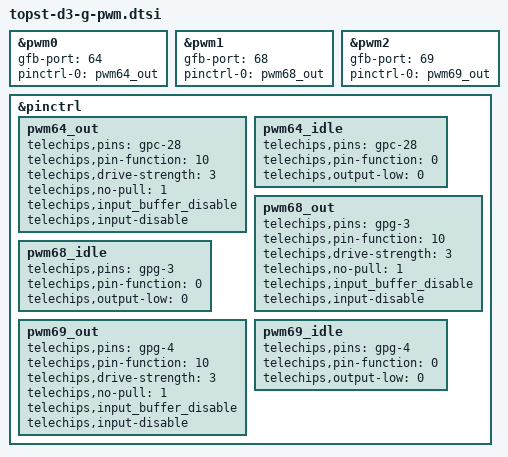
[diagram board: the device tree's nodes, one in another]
// SPDX-License-Identifier: (GPL-2.0-or-later OR MIT)
/*
 * Copyright (C) 2023 Telechips Inc.
 */
 
#include <dt-bindings/gpio/gpio.h>
#include <dt-bindings/interrupt-controller/arm-gic.h>
&pwm0 {
    status = "okay";
    gfb-port = <64>;
    pinctrl-names = "default";
    pinctrl-0 = <&pwm64_out>;
};
&pwm1 {
    status = "okay";
    gfb-port = <68>;
    pinctrl-names = "default";
    pinctrl-0 = <&pwm68_out>;
};
&pwm2 {
    status = "okay";
    gfb-port = <69>;
    pinctrl-names = "default";
    pinctrl-0 = <&pwm69_out>;
};
&pinctrl {
    //RPI GPIO_C28/ PWM PIN12
    pwm64_out: pwm64_out {
        telechips,pins = "gpc-28";
        telechips,pin-function = <10>;
        telechips,drive-strength = <3>;
        telechips,no-pull = <1>;
        telechips,input_buffer_disable;
        telechips,input-disable;
    };
    pwm64_idle: pwm64_idle {
        telechips,pins = "gpc-28";
        telechips,pin-function = <0>;
        telechips,output-low = <0>;
    };
    //RPI GPIO_G03/ PWM PIN33
    pwm68_out: pwm68_out {
        telechips,pins = "gpg-3";
        telechips,pin-function = <10>;
        telechips,drive-strength = <3>;
        telechips,no-pull = <1>;
        telechips,input_buffer_disable;
        telechips,input-disable;
    };
    pwm68_idle: pwm68_idle {
        telechips,pins = "gpg-3";
        telechips,pin-function = <0>;
        telechips,output-low = <0>;
    };

    //RPI GPIO_G04/ PWM PIN32
    pwm69_out: pwm69_out {
        telechips,pins = "gpg-4";
        telechips,pin-function = <10>;
        telechips,drive-strength = <3>;
        telechips,no-pull = <1>;
        telechips,input_buffer_disable;
        telechips,input-disable;
    };
    pwm69_idle: pwm69_idle {
        telechips,pins = "gpg-4";
        telechips,pin-function = <0>;
        telechips,output-low = <0>;
    };
};
